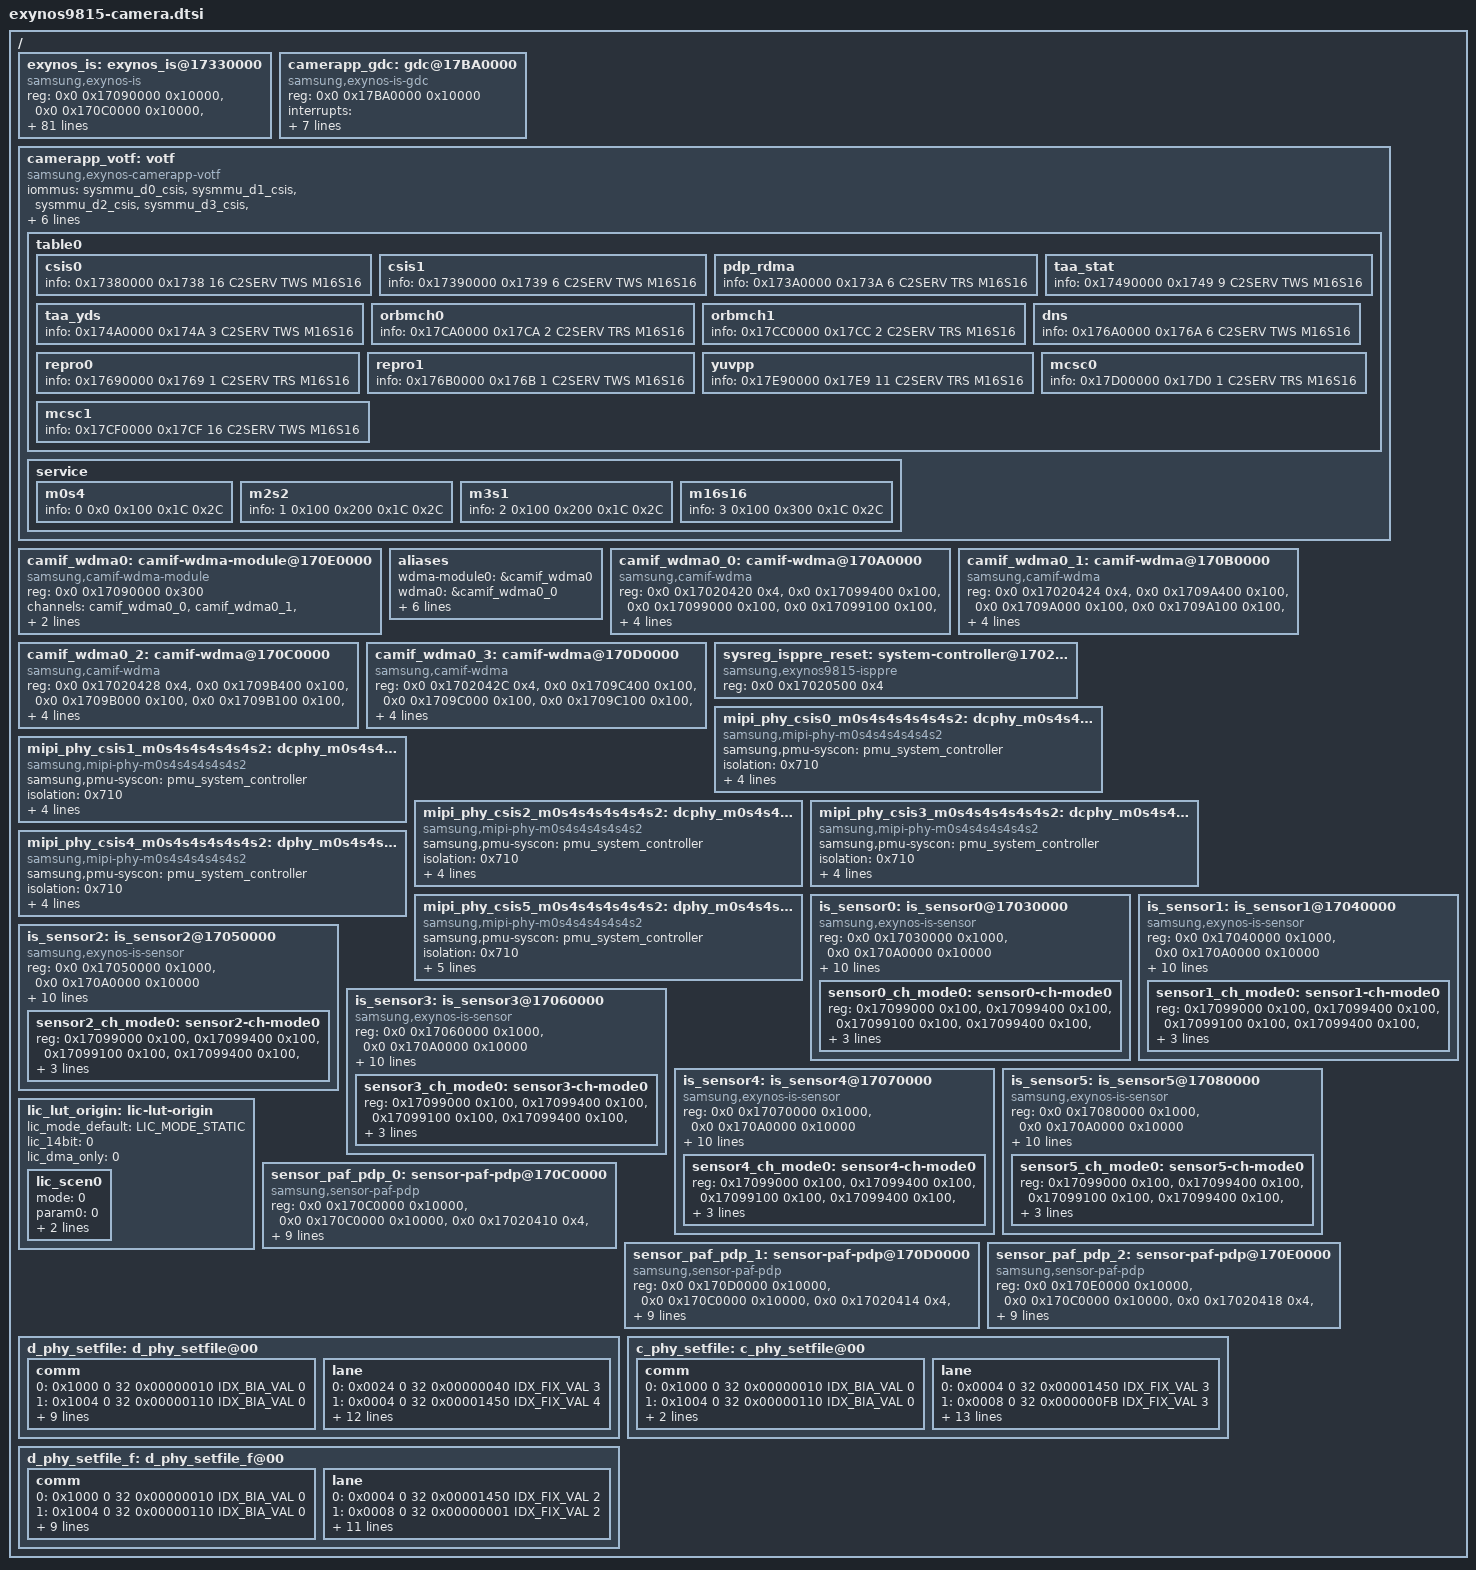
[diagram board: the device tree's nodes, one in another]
/*
 * SAMSUNG EXYNOS9815 SoC camera device tree source
 *
 * Copyright (c) 2020 Samsung Electronics Co., Ltd.
 *		http://www.samsung.com
 *
 * SAMSUNG EXYNOS9815 SoC camera device nodes are listed in this file.
 * EXYNOS9815 based board files can include this file and provide
 * values for board specfic bindings.
 *
 * This program is free software; you can redistribute it and/or modify
 * it under the terms of the GNU General Public License version 2 as
 * published by the Free Software Foundation.
 */

#include <dt-bindings/clock/s5e9815.h>
#include <dt-bindings/interrupt-controller/arm-gic.h>
#include <dt-bindings/interrupt-controller/s5e9815.h>
#include <dt-bindings/camera/exynos_is_dt.h>
#include <dt-bindings/camera/votf.h>
#include "s5e9815-pinctrl.dtsi"

/ {
	exynos_is: exynos_is@17330000 {
		compatible = "samsung,exynos-is";
		reg = <0x0 0x17090000 0x10000>, /* CSIS DMA  */
			<0x0 0x170C0000 0x10000>, /* PDP CORE0 */
			<0x0 0x170D0000 0x10000>, /* PDP CORE1 */
			<0x0 0x170E0000 0x10000>, /* PDP CORE2 */
			<0x0 0x17440000 0x30000>, /* TAA0 */
			<0x0 0x17440000 0x30000>, /* TAA1 */
			<0x0 0x17440000 0x30000>, /* TAA2 */
			<0x0 0x17090000 0x10000>, /* ZSL/STRIP DMA  */
			<0x0 0x17C90000 0x10000>, /* ORBMCH_0 */
			<0x0 0x17CB0000 0x10000>, /* ORBMCH_1 */
			<0x0 0x17A30000 0x40000>, /* ITP */
			<0x0 0x17960000 0x40000>, /* TNR(MCFP0) */
			<0x0 0x179A0000 0x40000>, /* TNR(MCFP1) */
			<0x0 0x17650000 0x40000>, /* DNS */
			<0x0 0x17E50000 0x40000>, /* YUVPP */
			<0x0 0x17B60000 0x40000>; /* MCSC */
		interrupts = <0 INTREQ__TAA_CH0_0 IRQ_TYPE_LEVEL_HIGH>, /*TAA0_0 */
			   <0 INTREQ__TAA_CH0_1 IRQ_TYPE_LEVEL_HIGH>,   /* TAA0_1 */
			   <0 INTREQ__ZSL_DMA0 IRQ_TYPE_LEVEL_HIGH>,    /* ZSL_DMA_0 */
			   <0 INTREQ__STRP_DMA0 IRQ_TYPE_LEVEL_HIGH>,    /* STRP_DMA_0 */

			   <0 INTREQ__TAA_CH1_0 IRQ_TYPE_LEVEL_HIGH>, /*TAA1_0 */
			   <0 INTREQ__TAA_CH1_1 IRQ_TYPE_LEVEL_HIGH>,   /* TAA1_1 */
			   <0 INTREQ__ZSL_DMA1 IRQ_TYPE_LEVEL_HIGH>,    /* ZSL_DMA_1 */
			   <0 INTREQ__STRP_DMA1 IRQ_TYPE_LEVEL_HIGH>,    /* STRP_DMA_1 */

			   <0 INTREQ__TAA_CH2_0 IRQ_TYPE_LEVEL_HIGH>, /*TAA2_0 */
			   <0 INTREQ__TAA_CH2_1 IRQ_TYPE_LEVEL_HIGH>,   /* TAA2_1 */
			   <0 INTREQ__ZSL_DMA2 IRQ_TYPE_LEVEL_HIGH>,    /* ZSL_DMA_2 */
			   <0 INTREQ__STRP_DMA2 IRQ_TYPE_LEVEL_HIGH>,    /* STRP_DMA_2 */

			   <0 INTREQ__ORBMCH0 IRQ_TYPE_LEVEL_HIGH>, /* ORBMCH_0 */
			   <0 INTREQ__ORBMCH1 IRQ_TYPE_LEVEL_HIGH>, /* ORBMCH_1 */

			   <0 INTREQ__DNS0_0 IRQ_TYPE_LEVEL_HIGH>,    /* ITP_0 */
			   <0 INTREQ__DNS0_1 IRQ_TYPE_LEVEL_HIGH>,    /* ITP_1 */
			   <0 INTREQ__TNR_0 IRQ_TYPE_LEVEL_HIGH>,     /* TNR_0 */
			   <0 INTREQ__TNR_1 IRQ_TYPE_LEVEL_HIGH>,     /* TNR_1 */
			   <0 INTREQ__YUVPP IRQ_TYPE_LEVEL_HIGH>,     /* YUVPP */
			   <0 INTREQ__MCSC_OTF0 IRQ_TYPE_LEVEL_HIGH>;   /* MCSC_0 */
		pinctrl-names = "default","release";
		pinctrl-0 = <>;
		pinctrl-1 = <>;
		clocks = <&clock GATE_U_CLKINV_MCLK0_QCH>,
		      <&clock GATE_U_CLKINV_MCLK1_QCH>,
		      <&clock GATE_U_CLKINV_MCLK2_QCH>,
		      <&clock GATE_U_CLKINV_MCLK3_QCH>,
		      <&clock GATE_U_CLKINV_MCLK4_QCH>,
		      <&clock GATE_U_CLKINV_MCLK5_QCH>,

		      <&clock DOUT_CLKCMU_CIS_CLK0>,
		      <&clock DOUT_CLKCMU_CIS_CLK1>,
		      <&clock DOUT_CLKCMU_CIS_CLK2>,
		      <&clock DOUT_CLKCMU_CIS_CLK3>,
		      <&clock DOUT_CLKCMU_CIS_CLK4>,
		      <&clock DOUT_CLKCMU_CIS_CLK5>,

		      <&clock GATE_CSISX6_QCH_DMA>,

		      <&clock GATE_MIPI_PHY_LINK_WRAP_QCH_CSIS0>,
		      <&clock GATE_MIPI_PHY_LINK_WRAP_QCH_CSIS1>,
		      <&clock GATE_MIPI_PHY_LINK_WRAP_QCH_CSIS2>,
		      <&clock GATE_MIPI_PHY_LINK_WRAP_QCH_CSIS3>,
		      <&clock GATE_MIPI_PHY_LINK_WRAP_QCH_CSIS4>,
		      <&clock GATE_MIPI_PHY_LINK_WRAP_QCH_CSIS5>,

		      <&clock GATE_PDP_TOP_QCH_PDP_TOP>,
		      <&clock GATE_SIPU_TAA_QCH>,
		      <&clock GATE_ORBMCH0_QCH>,
		      <&clock GATE_ORBMCH1_QCH>,
		      <&clock GATE_TNR_CMU_TNR_QCH>,
		      <&clock GATE_DNS_QCH>,
		      <&clock GATE_ITP_QCH>,
		      <&clock GATE_YUVPP_TOP_QCH>,
		      <&clock GATE_MCSC_QCH>,
		      <&clock GATE_GDC_QCH>;
		clock-names = "GATE_U_CLKINV_MCLK0_QCH",
			"GATE_U_CLKINV_MCLK1_QCH",
			"GATE_U_CLKINV_MCLK2_QCH",
			"GATE_U_CLKINV_MCLK3_QCH",
			"GATE_U_CLKINV_MCLK4_QCH",
			"GATE_U_CLKINV_MCLK5_QCH",

			"DOUT_CLKCMU_CIS_CLK0",
			"DOUT_CLKCMU_CIS_CLK1",
			"DOUT_CLKCMU_CIS_CLK2",
			"DOUT_CLKCMU_CIS_CLK3",
			"DOUT_CLKCMU_CIS_CLK4",
			"DOUT_CLKCMU_CIS_CLK5",

			"GATE_CSISX6_QCH_DMA",

			"GATE_MIPI_PHY_LINK_WRAP_QCH_CSIS0",
			"GATE_MIPI_PHY_LINK_WRAP_QCH_CSIS1",
			"GATE_MIPI_PHY_LINK_WRAP_QCH_CSIS2",
			"GATE_MIPI_PHY_LINK_WRAP_QCH_CSIS3",
			"GATE_MIPI_PHY_LINK_WRAP_QCH_CSIS4",
			"GATE_MIPI_PHY_LINK_WRAP_QCH_CSIS5",

			"GATE_PDP_TOP_QCH_PDP_TOP",
			"GATE_SIPU_TAA_QCH",
			"GATE_ORBMCH0_QCH",
			"GATE_ORBMCH1_QCH",
			"GATE_TNR_CMU_TNR_QCH",
			"GATE_DNS_QCH",
			"GATE_ITP_QCH",
			"GATE_YUVPP_TOP_QCH",
			"GATE_MCSC_QCH",
			"GATE_GDC_QCH";
		status = "ok";
		iommus = <&sysmmu_d0_csis>,
		       <&sysmmu_d1_csis>,
		       <&sysmmu_d2_csis>,
		       <&sysmmu_d3_csis>,
		       <&sysmmu_d_taa>,
		       <&sysmmu_d_yuvpp>,
		       <&sysmmu_d0_dns>,
		       <&sysmmu_d1_dns>,
		       <&sysmmu_d0_mcsc>,
		       <&sysmmu_d2_mcsc>,
		       <&sysmmu_d0_tnr>,
		       <&sysmmu_d1_tnr>,
		       <&sysmmu_d2_tnr>,
		       <&sysmmu_d3_tnr>;
		samsung,iommu-group = <&iommu_group_is>;
		#cooling-cells = <2>; /* min followed by max */
		ewf-index = <EWF_GRP_CAM>;
		list-scen-bts = "camera_default", "camera_heavy";
		num_of_3aa = <3>;
		num_of_lme = <2>;
		num_of_isp = <1>;
		num_of_mcsc = <1>;
		num_of_vra = <0>;
		num_of_clh = <0>;
		num_of_ypp = <1>;

		memory-region = <&camera_rmem>;
	};

	camerapp_gdc: gdc@17BA0000 {
		compatible = "samsung,exynos-is-gdc";
		reg = <0x0 0x17BA0000 0x10000>; /* GDC */
		interrupts = <0 INTREQ__GDC_IRQ IRQ_TYPE_LEVEL_HIGH>; /* GDC */
		pinctrl-names = "default","release";
		pinctrl-0 = <>;
		pinctrl-1 = <>;
		clocks = <&clock GATE_GDC_QCH>;
		clock-names = "gate";
		status = "okay";
		iommus = <&sysmmu_d1_mcsc>;
		samsung,iommu-group = <&iommu_group_camerapp_gdc>;
		#cooling-cells = <2>; /* min followed by max */
		dma-coherent;
	};

	camerapp_votf: votf {
		compatible = "samsung,exynos-camerapp-votf";
		status = "okay";
		iommus = <&sysmmu_d0_csis>,
				<&sysmmu_d1_csis>,
				<&sysmmu_d2_csis>,
				<&sysmmu_d3_csis>,
				<&sysmmu_d_taa>,
				<&sysmmu_d_yuvpp>,
				<&sysmmu_d0_dns>,
				<&sysmmu_d1_dns>,
				<&sysmmu_d0_mcsc>,
				<&sysmmu_d2_mcsc>,
				<&sysmmu_d0_tnr>,
				<&sysmmu_d1_tnr>,
				<&sysmmu_d2_tnr>,
				<&sysmmu_d3_tnr>;
		samsung,iommu-group = <&iommu_group_is>;
		use_axi;

		table0{
			/* base address, ip num, id cnt, C2SERV/C2AGENT, TWS/TRS, module type */
			csis0    { info = <0x17380000 0x1738 16 C2SERV TWS M16S16>; };
			csis1    { info = <0x17390000 0x1739 6  C2SERV TWS M16S16>; };
			pdp_rdma { info = <0x173A0000 0x173A 6  C2SERV TRS M16S16>; };
			taa_stat { info = <0x17490000 0x1749 9 C2SERV TWS M16S16>; };
			taa_yds  { info = <0x174A0000 0x174A 3  C2SERV TWS M16S16>; };
			orbmch0  { info = <0x17CA0000 0x17CA 2  C2SERV TRS M16S16>; };
			orbmch1  { info = <0x17CC0000 0x17CC 2  C2SERV TRS M16S16>; };
			dns      { info = <0x176A0000 0x176A 6  C2SERV TWS M16S16>; };
			repro0   { info = <0x17690000 0x1769 1  C2SERV TRS M16S16>; };
			repro1   { info = <0x176B0000 0x176B 1  C2SERV TWS M16S16>; };
			yuvpp    { info = <0x17E90000 0x17E9 11 C2SERV TRS M16S16>; };
			mcsc0    { info = <0x17D00000 0x17D0 1  C2SERV TRS M16S16>; };
			mcsc1    { info = <0x17CF0000 0x17CF 16 C2SERV TWS M16S16>; };
			/* gdc0     { info = <0x17BC0000 0x17BC 2  C2SERV TRS M16S16>; }; */
			/* gdc1     { info = <0x17BB0000 0x17BB 2  C2SERV TWS M16S16>; }; */
		};

		service {
			/* num, tws addr, trs addr, tws gap, trs gap */
			m0s4 { info = <0 0x0 0x100 0x1C 0x2C>; };
			m2s2 { info = <1 0x100 0x200 0x1C 0x2C>; };
			m3s1 { info = <2 0x100 0x200 0x1C 0x2C>; };
			m16s16 { info = <3 0x100 0x300 0x1C 0x2C>; };
		};
	};

	camif_wdma0: camif-wdma-module@170E0000 {
		compatible = "samsung,camif-wdma-module";
		reg = <0x0 0x17090000 0x300>;
		reg-names = "ctl";
		channels = <&camif_wdma0_0>,
			<&camif_wdma0_1>,
			<&camif_wdma0_2>,
			<&camif_wdma0_3>;
		samsung,quirks = "has test pattern gen";
	};

	aliases {
		wdma-module0 = &camif_wdma0;
	};

	camif_wdma0_0: camif-wdma@170A0000 {
		compatible = "samsung,camif-wdma";
		reg = <0x0 0x17020420 0x4>,	/* input MUX */
			<0x0 0x17099400 0x100>,	/* CTL */
			<0x0 0x17099000 0x100>,	/* VC0 */
			<0x0 0x17099100 0x100>,	/* VC1 */
			<0x0 0x17099200 0x100>,	/* VC2 */
			<0x0 0x17099300 0x100>;	/* VC3 */
		reg-names = "mux", "ctl", "vc0", "vc1", "vc2", "vc3";
		interrupts = <GIC_SPI INTREQ__CSIS_DMA0 IRQ_TYPE_LEVEL_HIGH>;
		interrupt-names = "dma";
		module = <&camif_wdma0>;
	};

	camif_wdma0_1: camif-wdma@170B0000 {
		compatible = "samsung,camif-wdma";
		reg = <0x0 0x17020424 0x4>,	/* input MUX */
			<0x0 0x1709A400 0x100>,	/* CTL */
			<0x0 0x1709A000 0x100>,	/* VC0 */
			<0x0 0x1709A100 0x100>,	/* VC1 */
			<0x0 0x1709A200 0x100>,	/* VC2 */
			<0x0 0x1709A300 0x100>;	/* VC3 */
		reg-names = "mux", "ctl", "vc0", "vc1", "vc2", "vc3";
		interrupts = <GIC_SPI INTREQ__CSIS_DMA1 IRQ_TYPE_LEVEL_HIGH>;
		interrupt-names = "dma";
		module = <&camif_wdma0>;
	};

	camif_wdma0_2: camif-wdma@170C0000 {
		compatible = "samsung,camif-wdma";
		reg = <0x0 0x17020428 0x4>,	/* input MUX */
			<0x0 0x1709B400 0x100>,	/* CTL */
			<0x0 0x1709B000 0x100>,	/* VC0 */
			<0x0 0x1709B100 0x100>,	/* VC1 */
			<0x0 0x1709B200 0x100>,	/* VC2 */
			<0x0 0x1709B300 0x100>;	/* VC3 */
		reg-names = "mux", "ctl", "vc0", "vc1", "vc2", "vc3";
		interrupts = <GIC_SPI INTREQ__CSIS_DMA2 IRQ_TYPE_LEVEL_HIGH>;
		interrupt-names = "dma";
		module = <&camif_wdma0>;
	};

	camif_wdma0_3: camif-wdma@170D0000 {
		compatible = "samsung,camif-wdma";
		reg = <0x0 0x1702042C 0x4>,	/* input MUX */
			<0x0 0x1709C400 0x100>,	/* CTL */
			<0x0 0x1709C000 0x100>,	/* VC0 */
			<0x0 0x1709C100 0x100>,	/* VC1 */
			<0x0 0x1709C200 0x100>,	/* VC2 */
			<0x0 0x1709C300 0x100>;	/* VC3 */
		reg-names = "mux", "ctl", "vc0", "vc1", "vc2", "vc3";
		interrupts = <GIC_SPI INTREQ__CSIS_DMA3 IRQ_TYPE_LEVEL_HIGH>;
		interrupt-names = "dma";
		module = <&camif_wdma0>;
	};

	aliases {
		wdma0 = &camif_wdma0_0;
		wdma1 = &camif_wdma0_1;
		wdma2 = &camif_wdma0_2;
		wdma3 = &camif_wdma0_3;
	};

	sysreg_isppre_reset: system-controller@17020500 {
		compatible = "samsung,exynos9815-isppre", "syscon";
		reg = <0x0 0x17020500 0x4>;
	};

	mipi_phy_csis0_m0s4s4s4s4s4s2: dcphy_m0s4s4s4s4s4s2_csi0@17020500 {
		/* DPHY 6.5 Gbps 4lane */
		/* CPHY 4.5 Gbps 3lane */
		compatible = "samsung,mipi-phy-m0s4s4s4s4s4s2";
		samsung,pmu-syscon = <&pmu_system_controller>;
		isolation = <0x710>; /* PMU address offset */
		samsung,reset-sysreg = <&sysreg_isppre_reset>;
		reset = <0>; /* reset bit */
		reg = <0x0 0x170A1300 0x500>;
		owner = <1>; /* 0: DSI,  1: CSI */
		#phy-cells = <1>;
	};

	mipi_phy_csis1_m0s4s4s4s4s4s2: dcphy_m0s4s4s4s4s4s2_csi1@17020500 {
		/* DPHY 6.5 Gbps 4lane */
		/* CPHY 4.5 Gbps 3lane */
		compatible = "samsung,mipi-phy-m0s4s4s4s4s4s2";
		samsung,pmu-syscon = <&pmu_system_controller>;
		isolation = <0x710>; /* PMU address offset */
		samsung,reset-sysreg = <&sysreg_isppre_reset>;
		reset = <1>; /* reset bit */
		reg = <0x0 0x170A1B00 0x500>;
		owner = <1>; /* 0: DSI,  1: CSI */
		#phy-cells = <1>;
	};

	mipi_phy_csis2_m0s4s4s4s4s4s2: dcphy_m0s4s4s4s4s4s2_csi2@17020500 {
		/* DPHY 6.5 Gbps 4lane */
		/* CPHY 4.5 Gbps 3lane */
		compatible = "samsung,mipi-phy-m0s4s4s4s4s4s2";
		samsung,pmu-syscon = <&pmu_system_controller>;
		isolation = <0x710>; /* PMU address offset */
		samsung,reset-sysreg = <&sysreg_isppre_reset>;
		reset = <2>; /* reset bit */
		reg = <0x0 0x170A2300 0x500>;
		owner = <1>; /* 0: DSI,  1: CSI */
		#phy-cells = <1>;
	};

	mipi_phy_csis3_m0s4s4s4s4s4s2: dcphy_m0s4s4s4s4s4s2_csi3@17020500 {
		/* DPHY 6.5 Gbps 4lane */
		/* CPHY 4.5 Gbps 3lane */
		compatible = "samsung,mipi-phy-m0s4s4s4s4s4s2";
		samsung,pmu-syscon = <&pmu_system_controller>;
		isolation = <0x710>; /* PMU address offset */
		samsung,reset-sysreg = <&sysreg_isppre_reset>;
		reset = <3>; /* reset bit */
		reg = <0x0 0x170A2B00 0x500>;
		owner = <1>; /* 0: DSI,  1: CSI */
		#phy-cells = <1>;
	};

	mipi_phy_csis4_m0s4s4s4s4s4s2: dphy_m0s4s4s4s4s4s2_csi4@17020500 {
		/* DPHY 6.5 Gbps 4lane */
		compatible = "samsung,mipi-phy-m0s4s4s4s4s4s2";
		samsung,pmu-syscon = <&pmu_system_controller>;
		isolation = <0x710>; /* PMU address offset */
		samsung,reset-sysreg = <&sysreg_isppre_reset>;
		reset = <4>; /* reset bit */
		reg = <0x0 0x170A3300 0x500>;
		owner = <1>; /* 0: DSI,  1: CSI */
		#phy-cells = <1>;
	};

	mipi_phy_csis5_m0s4s4s4s4s4s2: dphy_m0s4s4s4s4s4s2_csi5@17020500 {
		/* DPHY 6.5 Gbps 2lane */
		compatible = "samsung,mipi-phy-m0s4s4s4s4s4s2";
		samsung,pmu-syscon = <&pmu_system_controller>;
		isolation = <0x710>; /* PMU address offset */
		samsung,reset-sysreg = <&sysreg_isppre_reset>;
		reset = <5>; /* reset bit */
		reg = <0x0 0x170A3B00 0x100>, /* clock */
			<0x0 0x170A3600 0x200>; /* lane */
		reg-names = "clock", "lane";
		owner = <1>; /* 0: DSI,  1: CSI */
		#phy-cells = <1>;
	};

	is_sensor0: is_sensor0@17030000 {
		/* CSIS0 */
		compatible = "samsung,exynos-is-sensor";
		#address-cells = <1>;
		#size-cells = <1>;
		reg = <0x0 0x17030000 0x1000>, /* MIPI-CSI0 */
			<0x0 0x170A0000 0x10000>; /* PHY: M0S4S4S4S4S4S2 */
		reg-names = "csi", "phy";
		interrupts = <0 INTREQ__CSIS0 IRQ_TYPE_LEVEL_HIGH>, /*MIPI-CSI0 */
			<0 INTREQ__CSIS_DMA0 IRQ_TYPE_LEVEL_HIGH>,
			<0 INTREQ__CSIS_DMA0 IRQ_TYPE_LEVEL_HIGH>,
			<0 INTREQ__CSIS_DMA0 IRQ_TYPE_LEVEL_HIGH>,
			<0 INTREQ__CSIS_DMA0 IRQ_TYPE_LEVEL_HIGH>;
		interrupt-names = "csi",
			"mode0_VC0", "mode0_VC1","mode0_VC2","mode0_VC3";
		phys = <&mipi_phy_csis0_m0s4s4s4s4s4s2 0>;
		phy-names = "csis_dphy";
		phy_setfile = <&d_phy_setfile>;
		iommus = <&sysmmu_d0_csis>, <&sysmmu_d1_csis>;
		samsung,iommu-group = <&iommu_group_is>;

		/* without PAF HW */
		sensor0_ch_mode0: sensor0-ch-mode0 {
			reg = <0x17099000 0x100>, /* DMA0 VC0 */
				<0x17099400 0x100>, /* DMA0 Common */
				<0x17099100 0x100>, /* DMA0 VC1 */
				<0x17099400 0x100>, /* DMA0 Common */
				<0x17099200 0x100>, /* DMA0 VC2 */
				<0x17099400 0x100>, /* DMA0 Common */
				<0x17099300 0x100>, /* DMA0 VC3 */
				<0x17099400 0x100>; /* DMA0 Common */
			mux_reg = <0x17020420 0x4>; /* DMA0 input mux */
		};
	};

	is_sensor1: is_sensor1@17040000 {
		/* CSIS1 */
		compatible = "samsung,exynos-is-sensor";
		#address-cells = <1>;
		#size-cells = <1>;
		reg = <0x0 0x17040000 0x1000>, /* MIPI-CSI1 */
			<0x0 0x170A0000 0x10000>; /* PHY: M0S4S4S4S4S4S2 */
		reg-names = "csi", "phy";
		interrupts = <0 INTREQ__CSIS1 IRQ_TYPE_LEVEL_HIGH>, /* MIPI-CSI1 */
			<0 INTREQ__CSIS_DMA0 IRQ_TYPE_LEVEL_HIGH>,
			<0 INTREQ__CSIS_DMA0 IRQ_TYPE_LEVEL_HIGH>,
			<0 INTREQ__CSIS_DMA0 IRQ_TYPE_LEVEL_HIGH>,
			<0 INTREQ__CSIS_DMA0 IRQ_TYPE_LEVEL_HIGH>;
		interrupt-names = "csi",
			"mode0_VC0", "mode0_VC1","mode0_VC2","mode0_VC3";
		phys = <&mipi_phy_csis1_m0s4s4s4s4s4s2 0>;
		phy-names = "csis_dphy";
		phy_setfile = <&d_phy_setfile>;
		iommus = <&sysmmu_d0_csis>, <&sysmmu_d1_csis>;
		samsung,iommu-group = <&iommu_group_is>;

		/* without PAF HW */
		sensor1_ch_mode0: sensor1-ch-mode0 {
			reg = <0x17099000 0x100>, /* DMA0 VC0 */
				<0x17099400 0x100>, /* DMA0 Common */
				<0x17099100 0x100>, /* DMA0 VC1 */
				<0x17099400 0x100>, /* DMA0 Common */
				<0x17099200 0x100>, /* DMA0 VC2 */
				<0x17099400 0x100>, /* DMA0 Common */
				<0x17099300 0x100>, /* DMA0 VC3 */
				<0x17099400 0x100>; /* DMA0 Common */
			mux_reg = <0x17020420 0x4>; /* DMA0 input mux */
		};
	};

	is_sensor2: is_sensor2@17050000 {
		/* CSIS2 */
		compatible = "samsung,exynos-is-sensor";
		#address-cells = <1>;
		#size-cells = <1>;
		reg = <0x0 0x17050000 0x1000>, /* MIPI-CSI2 */
			<0x0 0x170A0000 0x10000>; /* PHY: M0S4S4S4S4S4S2 */
		reg-names = "csi", "phy";
		interrupts = <0 INTREQ__CSIS2 IRQ_TYPE_LEVEL_HIGH>, /* MIPI-CSI2 */
			<0 INTREQ__CSIS_DMA0 IRQ_TYPE_LEVEL_HIGH>,
			<0 INTREQ__CSIS_DMA0 IRQ_TYPE_LEVEL_HIGH>,
			<0 INTREQ__CSIS_DMA0 IRQ_TYPE_LEVEL_HIGH>,
			<0 INTREQ__CSIS_DMA0 IRQ_TYPE_LEVEL_HIGH>;
		interrupt-names = "csi",
			"mode0_VC0", "mode0_VC1","mode0_VC2","mode0_VC3";
		phys = <&mipi_phy_csis2_m0s4s4s4s4s4s2 0>;
		phy-names = "csis_dphy";
		phy_setfile = <&d_phy_setfile>;
		iommus = <&sysmmu_d0_csis>, <&sysmmu_d1_csis>;
		samsung,iommu-group = <&iommu_group_is>;

		/* without PAF HW */
		sensor2_ch_mode0: sensor2-ch-mode0 {
			reg = <0x17099000 0x100>, /* DMA0 VC0 */
				<0x17099400 0x100>, /* DMA0 Common */
				<0x17099100 0x100>, /* DMA0 VC1 */
				<0x17099400 0x100>, /* DMA0 Common */
				<0x17099200 0x100>, /* DMA0 VC2 */
				<0x17099400 0x100>, /* DMA0 Common */
				<0x17099300 0x100>, /* DMA0 VC3 */
				<0x17099400 0x100>; /* DMA0 Common */
			mux_reg = <0x17020420 0x4>; /* DMA0 input mux */
		};
	};

	is_sensor3: is_sensor3@17060000 {
		/* CSIS3 */
		compatible = "samsung,exynos-is-sensor";
		#address-cells = <1>;
		#size-cells = <1>;
		reg = <0x0 0x17060000 0x1000>, /* MIPI-CSI3 */
			<0x0 0x170A0000 0x10000>; /* PHY: M0S4S4S4S4S4S2 */
		reg-names = "csi", "phy";
		interrupts = <0 INTREQ__CSIS3 IRQ_TYPE_LEVEL_HIGH>, /* MIPI-CSI3 */
			<0 INTREQ__CSIS_DMA0 IRQ_TYPE_LEVEL_HIGH>,
			<0 INTREQ__CSIS_DMA0 IRQ_TYPE_LEVEL_HIGH>,
			<0 INTREQ__CSIS_DMA0 IRQ_TYPE_LEVEL_HIGH>,
			<0 INTREQ__CSIS_DMA0 IRQ_TYPE_LEVEL_HIGH>;
		interrupt-names = "csi",
			"mode0_VC0", "mode0_VC1","mode0_VC2","mode0_VC3";
		phys = <&mipi_phy_csis3_m0s4s4s4s4s4s2 0>;
		phy-names = "csis_dphy";
		phy_setfile = <&d_phy_setfile>;
		iommus = <&sysmmu_d0_csis>, <&sysmmu_d1_csis>;
		samsung,iommu-group = <&iommu_group_is>;

		/* without PAF HW */
		sensor3_ch_mode0: sensor3-ch-mode0 {
			reg = <0x17099000 0x100>, /* DMA0 VC0 */
				<0x17099400 0x100>, /* DMA0 Common */
				<0x17099100 0x100>, /* DMA0 VC1 */
				<0x17099400 0x100>, /* DMA0 Common */
				<0x17099200 0x100>, /* DMA0 VC2 */
				<0x17099400 0x100>, /* DMA0 Common */
				<0x17099300 0x100>, /* DMA0 VC3 */
				<0x17099400 0x100>; /* DMA0 Common */
			mux_reg = <0x17020420 0x4>; /* DMA0 input mux */
		};
	};

	is_sensor4: is_sensor4@17070000 {
		/* CSIS4 */
		compatible = "samsung,exynos-is-sensor";
		#address-cells = <1>;
		#size-cells = <1>;
		reg = <0x0 0x17070000 0x1000>, /* MIPI-CSI4 */
			<0x0 0x170A0000 0x10000>; /* PHY: M0S4S4S4S4S4S2 */
		reg-names = "csi", "phy";
		interrupts = <0 INTREQ__CSIS4 IRQ_TYPE_LEVEL_HIGH>, /* MIPI-CSI4 */
			<0 INTREQ__CSIS_DMA0 IRQ_TYPE_LEVEL_HIGH>,
			<0 INTREQ__CSIS_DMA0 IRQ_TYPE_LEVEL_HIGH>,
			<0 INTREQ__CSIS_DMA0 IRQ_TYPE_LEVEL_HIGH>,
			<0 INTREQ__CSIS_DMA0 IRQ_TYPE_LEVEL_HIGH>;
		interrupt-names = "csi",
			"mode0_VC0", "mode0_VC1","mode0_VC2","mode0_VC3";
		phys = <&mipi_phy_csis4_m0s4s4s4s4s4s2 0>;
		phy-names = "csis_dphy";
		phy_setfile = <&d_phy_setfile>;
		iommus = <&sysmmu_d0_csis>, <&sysmmu_d1_csis>;
		samsung,iommu-group = <&iommu_group_is>;

		/* without PAF HW */
		sensor4_ch_mode0: sensor4-ch-mode0 {
			reg = <0x17099000 0x100>, /* DMA0 VC0 */
				<0x17099400 0x100>, /* DMA0 Common */
				<0x17099100 0x100>, /* DMA0 VC1 */
				<0x17099400 0x100>, /* DMA0 Common */
				<0x17099200 0x100>, /* DMA0 VC2 */
				<0x17099400 0x100>, /* DMA0 Common */
				<0x17099300 0x100>, /* DMA0 VC3 */
				<0x17099400 0x100>; /* DMA0 Common */
			mux_reg = <0x17020420 0x4>; /* DMA0 input mux */
		};
	};

	is_sensor5: is_sensor5@17080000 {
		/* CSIS5 */
		compatible = "samsung,exynos-is-sensor";
		#address-cells = <1>;
		#size-cells = <1>;
		reg = <0x0 0x17080000 0x1000>, /* MIPI-CSI5 */
			<0x0 0x170A0000 0x10000>; /* PHY: M0S4S4S4S4S4S2 */
		reg-names = "csi", "phy";
		interrupts = <0 INTREQ__CSIS5 IRQ_TYPE_LEVEL_HIGH>, /* MIPI-CSI5 */
			<0 INTREQ__CSIS_DMA0 IRQ_TYPE_LEVEL_HIGH>,
			<0 INTREQ__CSIS_DMA0 IRQ_TYPE_LEVEL_HIGH>,
			<0 INTREQ__CSIS_DMA0 IRQ_TYPE_LEVEL_HIGH>,
			<0 INTREQ__CSIS_DMA0 IRQ_TYPE_LEVEL_HIGH>;
		interrupt-names = "csi",
			"mode0_VC0", "mode0_VC1","mode0_VC2","mode0_VC3";
		phys = <&mipi_phy_csis5_m0s4s4s4s4s4s2 0>;
		phy-names = "csis_dphy";
		phy_setfile = <&d_phy_setfile_f>; /* 2+2 lane */
		iommus = <&sysmmu_d0_csis>, <&sysmmu_d1_csis>;
		samsung,iommu-group = <&iommu_group_is>;

		/* without PAF HW */
		sensor5_ch_mode0: sensor5-ch-mode0 {
			reg = <0x17099000 0x100>, /* DMA0 VC0 */
				<0x17099400 0x100>, /* DMA0 Common */
				<0x17099100 0x100>, /* DMA0 VC1 */
				<0x17099400 0x100>, /* DMA0 Common */
				<0x17099200 0x100>, /* DMA0 VC2 */
				<0x17099400 0x100>, /* DMA0 Common */
				<0x17099300 0x100>, /* DMA0 VC3 */
				<0x17099400 0x100>; /* DMA0 Common */
			mux_reg = <0x17020420 0x4>; /* DMA0 input mux */
		};
	};

	lic_lut_origin: lic-lut-origin {
		#define LIC_MODE_DYNAMIC	(0)
		#define LIC_MODE_STATIC		(1)
		#define LIC_PATH_OTF		(0)
		#define LIC_PATH_DMA		(1)

		lic_mode_default = <LIC_MODE_STATIC>;
		lic_14bit = <0>;
		lic_dma_only = <0>; /* Use this when NOT using OTF input at all. */

		/*
		 * When DYNAMIC mode is selected, param means enable limitation for DMA path.
		 * Example:
		 * @ mode = <LIC_MODE_DYNAMIC>;
		 * @ param0 = <LIC_PATH_OTF>;
		 * @ param1 = <LIC_PATH_DMA>;
		 * @ param2 = <LIC_PATH_OTF>;
		 *
		 * When STATIC mode is selected, param means buffer size for each context.
		 * Example:
		 * @ mode = <LIC_MODE_STAIC>;
		 * @ param0 = <3584>;
		 * @ param1 = <3583>;
		 * @ param2 = <1>;
		 *
		 * The lic_scen0 is not abailable. If the index of LUT is "0", the selection is skipped.
		 */
		lic_scen0 { /* Reserved */
			mode = <0>;
			param0 = <0>;
			param1 = <0>;
			param2 = <0>;
		};
	};

	sensor_paf_pdp_0: sensor-paf-pdp@170C0000 {
		/* PDP CORE0 */
		compatible = "samsung,sensor-paf-pdp";
		reg = <0x0 0x170C0000 0x10000>, /* PDP CORE0 */
			<0x0 0x170C0000 0x10000>, /* PDP CORE0: For common regiser */
			<0x0 0x17020410 0x4>, /* PDP input mux(CSIS_PDP_SC_CON0) in SYSREG */
			<0x0 0x17020430 0x4>, /* PDP input vc mux(CSIS_PDP_VC_CON0) in SYSREG */
			<0x0 0x17020480 0x4>; /* CSIS_PDP_SC_PDP_IN_EN in SYSREG */
		reg-names = "core", "common", "mux", "vc_mux", "en";
		interrupts = <0 INTREQ__PDP0 IRQ_TYPE_LEVEL_HIGH>,
			<0 INTREQ__PDP1 IRQ_TYPE_LEVEL_HIGH>;
		mux =  <0 1 2 3 4 5>; /* <csi0 csi1 csi2 csi3 csi4 csi5> */
		vc_mux = <0x1 0x1 0x1 0x1 0x1 0x1>; /* <csi0 csi1 csi2 csi3 csi4 csi5> */
		en =  <0 1 2 3 4 5>; /* bit postion: <csi0 csi1 csi2 csi3 csi4 csi5> */
		leader; /* have RDMA & create video node */
		lic_lut = <&lic_lut_origin>;
	};

	sensor_paf_pdp_1: sensor-paf-pdp@170D0000 {
		/* PDP CORE0 */
		compatible = "samsung,sensor-paf-pdp";
		reg = <0x0 0x170D0000 0x10000>, /* PDP CORE0 */
			<0x0 0x170C0000 0x10000>, /* PDP CORE0: For common regiser */
			<0x0 0x17020414 0x4>, /* PDP input mux(CSIS_PDP_SC_CON0) in SYSREG */
			<0x0 0x17020434 0x4>, /* PDP input vc mux(CSIS_PDP_VC_CON0) in SYSREG */
			<0x0 0x17020484 0x4>; /* CSIS_PDP_SC_PDP_IN_EN in SYSREG */
		reg-names = "core", "common", "mux", "vc_mux", "en";
		interrupts = <0 INTREQ__PDP2 IRQ_TYPE_LEVEL_HIGH>,
			<0 INTREQ__PDP3 IRQ_TYPE_LEVEL_HIGH>;
		mux =  <0 1 2 3 4 5>; /* <csi0 csi1 csi2 csi3 csi4 csi5> */
		vc_mux = <0x1 0x1 0x1 0x1 0x1 0x1>; /* <csi0 csi1 csi2 csi3 csi4 csi5> */
		en =  <0 1 2 3 4 5>; /* bit postion: <csi0 csi1 csi2 csi3 csi4 csi5> */
		leader; /* have RDMA & create video node */
		lic_lut = <&lic_lut_origin>;
	};

	sensor_paf_pdp_2: sensor-paf-pdp@170E0000 {
		/* PDP CORE0 */
		compatible = "samsung,sensor-paf-pdp";
		reg = <0x0 0x170E0000 0x10000>, /* PDP CORE0 */
			<0x0 0x170C0000 0x10000>, /* PDP CORE0: For common regiser */
			<0x0 0x17020418 0x4>, /* PDP input mux(CSIS_PDP_SC_CON0) in SYSREG */
			<0x0 0x17020438 0x4>, /* PDP input vc mux(CSIS_PDP_VC_CON0) in SYSREG */
			<0x0 0x17020488 0x4>; /* CSIS_PDP_SC_PDP_IN_EN in SYSREG */
		reg-names = "core", "common", "mux", "vc_mux", "en";
		interrupts = <0 INTREQ__PDP4 IRQ_TYPE_LEVEL_HIGH>,
			<0 INTREQ__PDP5 IRQ_TYPE_LEVEL_HIGH>;
		mux =  <0 1 2 3 4 5>; /* <csi0 csi1 csi2 csi3 csi4 csi5> */
		vc_mux = <0x1 0x1 0x1 0x1 0x1 0x1>; /* <csi0 csi1 csi2 csi3 csi4 csi5> */
		en =  <0 1 2 3 4 5>; /* bit postion: <csi0 csi1 csi2 csi3 csi4 csi5> */
		leader; /* have RDMA & create video node */
		lic_lut = <&lic_lut_origin>;
	};

	aliases {
		pdp0 = &sensor_paf_pdp_0;
		pdp1 = &sensor_paf_pdp_1;
		pdp2 = &sensor_paf_pdp_2;
	};

	/*
	 * phy setfile
	 * <addr, bit_start, bit_width, val, index, max_lane>
	 */
	d_phy_setfile: d_phy_setfile@00 {
		comm {
			/* bias */
			0  = <0x1000 0 32 0x00000010 IDX_BIA_VAL 0>; /* M_BIAS_CON0 */
			1  = <0x1004 0 32 0x00000110 IDX_BIA_VAL 0>; /* M_BIAS_CON1 */
			2  = <0x1008 0 32 0x00003223 IDX_BIA_VAL 0>; /* M_BIAS_CON2 */

			/* clock */
			3  = <0x0004 0 32 0x00001450 IDX_FIX_VAL 0>; /* SC_GNR_CON1 */
			4  = <0x0008 0 32 0x00000001 IDX_FIX_VAL 0>; /* SC_ANA_CON0 */
			5  = <0x000C 0 32 0x0000E800 IDX_FIX_VAL 0>; /* SC_ANA_CON1 */
			6  = <0x0010 0 32 0x00000004 IDX_FIX_VAL 0>; /* SC_ANA_CON2 */
			7  = <0x0014 0 32 0x00008600 IDX_FIX_VAL 0>; /* SC_ANA_CON3 */
			8  = <0x0018 0 32 0x00004000 IDX_FIX_VAL 0>; /* SC_ANA_CON4 */
			9  = <0x0030 0 32 0x00000301 IDX_FIX_VAL 0>; /* SC_TIME_CON0 */
			/* Enable should be set at last. */
			10 = <0x0000 0 32 0x00000001 IDX_FIX_VAL 0>; /* SC_GNR_CON0, Phy clock enable */
		};

		lane {
			0  = <0x0024 0 32 0x00000040 IDX_FIX_VAL 3>; /* SD_ANA_CON7 */
			1  = <0x0004 0 32 0x00001450 IDX_FIX_VAL 4>; /* SD_GNR_CON1 */
			2  = <0x0008 0 32 0x00000001 IDX_FIX_VAL 4>; /* SD_ANA_CON0 */
			3  = <0x000C 0 32 0x0000EA40 IDX_FIX_VAL 4>; /* SD_ANA_CON1 */
			4  = <0x0014 0 32 0x00008600 IDX_FIX_VAL 4>; /* SD_ANA_CON3 */
			5  = <0x0018 0 32 0x00004000 IDX_FIX_VAL 4>; /* SD_ANA_CON4 */
			6  = <0x0034 0 32 0x00000003 IDX_FIX_VAL 4>; /* SD_TIME_CON1 */
			7  = <0x0050 0 32 0x0000081A IDX_FIX_VAL 4>; /* SD_DESKEW_CON4 */
			8  = <0x0010 0 32 0x00000004 IDX_FIX_VAL 4>; /* SD_ANA_CON2 */
			9  = <0x0010 8  2 0x00000000 IDX_SKW_DLY 4>; /* SD_ANA_CON2 */
			10 = <0x0030 0  8 0x00000000 IDX_STL_VAL 4>; /* SD_TIME_CON0 */
			11 = <0x0030 8  1 0x00000000 IDX_STL_CLK 4>; /* SD_TIME_CON0 */
			12 = <0x0040 0  1 0x00000000 IDX_SKW_CAL 4>; /* SD_DESKEW_CON0 */
			/* Enable should be set at last. */
			13 = <0x0000 0 32 0x00000001 IDX_FIX_VAL 4>; /* SD_GNR_CON0 , Phy data enable */
		};
	};

	c_phy_setfile: c_phy_setfile@00 {
		comm {
			/* bias */
			0  = <0x1000 0 32 0x00000010 IDX_BIA_VAL 0>; /* M_BIAS_CON0 */
			1  = <0x1004 0 32 0x00000110 IDX_BIA_VAL 0>; /* M_BIAS_CON1 */
			2  = <0x1008 0 32 0x00003223 IDX_BIA_VAL 0>; /* M_BIAS_CON2 */
			3  = <0x1010 0 32 0x00000040 IDX_BIA_VAL 0>; /* M_BIAS_CON4 */
		};

		lane {
			0  = <0x0004 0 32 0x00001450 IDX_FIX_VAL 3>; /* SD_GNR_CON1 */
			1  = <0x0008 0 32 0x000000FB IDX_FIX_VAL 3>; /* SD_ANA_CON0 */
			2  = <0x000C 0 32 0x0000B640 IDX_FIX_VAL 3>; /* SD_ANA_CON1 */
			3  = <0x0010 0 32 0x00000005 IDX_FIX_VAL 3>; /* SD_ANA_CON2 */
			4  = <0x0014 0 32 0x00008600 IDX_FIX_VAL 3>; /* SD_ANA_CON3 */
			5  = <0x0018 0 32 0x00004000 IDX_FIX_VAL 3>; /* SD_ANA_CON4 */
			6  = <0x001c 0 32 0x00000200 IDX_FIX_VAL 3>; /* SD_ANA_CON5 */
			7  = <0x0020 0 32 0x00000638 IDX_FIX_VAL 3>; /* SD_ANA_CON6 */
			8  = <0x0024 0 32 0x00000040 IDX_FIX_VAL 3>; /* SD_ANA_CON7 */
			9  = <0x0030 0  8 0x00000000 IDX_STL_VAL 3>; /* SD_TIME_CON0 */
			10 = <0x0030 8  1 0x00000000 IDX_STL_CLK 3>; /* SD_TIME_CON0 */
			11 = <0x0034 0 32 0x00000034 IDX_FIX_VAL 3>; /* SD_TIME_CON1 */
			13 = <0x0064 0 32 0x00001501 IDX_FIX_VAL 3>; /* SD_CRC_CON1 */
			14 = <0x0068 0 32 0x00000033 IDX_FIX_VAL 3>; /* SD_CRC_CON2 */
			/* Enable should be set at last. */
			15 = <0x0000 0 32 0x00000001 IDX_FIX_VAL 3>; /* SD_GNR_CON0 , Phy data enable */
		};
	};

	/*
	 * 2+2 lane
	 */
	d_phy_setfile_f: d_phy_setfile_f@00 {
		comm {
			/* bias */
			0  = <0x1000 0 32 0x00000010 IDX_BIA_VAL 0>; /* M_BIAS_CON0 */
			1  = <0x1004 0 32 0x00000110 IDX_BIA_VAL 0>; /* M_BIAS_CON1 */
			2  = <0x1008 0 32 0x00003223 IDX_BIA_VAL 0>; /* M_BIAS_CON2 */

			/* clock */
			3  = <0x0004 0 32 0x00001450 IDX_FIX_VAL 0>; /* SC_GNR_CON1 */
			4  = <0x0008 0 32 0x00000001 IDX_FIX_VAL 0>; /* SC_ANA_CON0 */
			5  = <0x000C 0 32 0x0000E800 IDX_FIX_VAL 0>; /* SC_ANA_CON1 */
			6  = <0x0010 0 32 0x00000004 IDX_FIX_VAL 0>; /* SC_ANA_CON2 */
			7  = <0x0014 0 32 0x00008600 IDX_FIX_VAL 0>; /* SC_ANA_CON3 */
			8  = <0x0018 0 32 0x00004000 IDX_FIX_VAL 0>; /* SC_ANA_CON4 */
			9  = <0x0030 0 32 0x00000301 IDX_FIX_VAL 0>; /* SC_TIME_CON0 */
			/* Enable should be set at last. */
			10 = <0x0000 0 32 0x00000001 IDX_FIX_VAL 0>; /* SC_GNR_CON0, Phy clock enable */
		};

		lane {
			0  = <0x0004 0 32 0x00001450 IDX_FIX_VAL 2>; /* SD_GNR_CON1 */
			1  = <0x0008 0 32 0x00000001 IDX_FIX_VAL 2>; /* SD_ANA_CON0 */
			2  = <0x000C 0 32 0x0000EA40 IDX_FIX_VAL 2>; /* SD_ANA_CON1 */
			3  = <0x0014 0 32 0x00008600 IDX_FIX_VAL 2>; /* SD_ANA_CON3 */
			4  = <0x0018 0 32 0x00004000 IDX_FIX_VAL 2>; /* SD_ANA_CON4 */
			5  = <0x0034 0 32 0x00000003 IDX_FIX_VAL 2>; /* SD_TIME_CON1 */
			6  = <0x0050 0 32 0x0000081A IDX_FIX_VAL 2>; /* SD_DESKEW_CON4 */
			7  = <0x0010 0 32 0x00008084 IDX_FIX_VAL 2>; /* SD_ANA_CON2 */
			8  = <0x0010 8  2 0x00000000 IDX_SKW_DLY 2>; /* SD_ANA_CON2 */
			9  = <0x0030 0  8 0x00000000 IDX_STL_VAL 2>; /* SD_TIME_CON0 */
			10 = <0x0030 8  1 0x00000000 IDX_STL_CLK 2>; /* SD_TIME_CON0 */
			11 = <0x0040 0  1 0x00000000 IDX_SKW_CAL 2>; /* SD_DESKEW_CON0 */
			/* Enable should be set at last. */
			12 = <0x0000 0 32 0x00000001 IDX_FIX_VAL 2>; /* SD_GNR_CON0 , Phy data enable */
		};
	};
};
